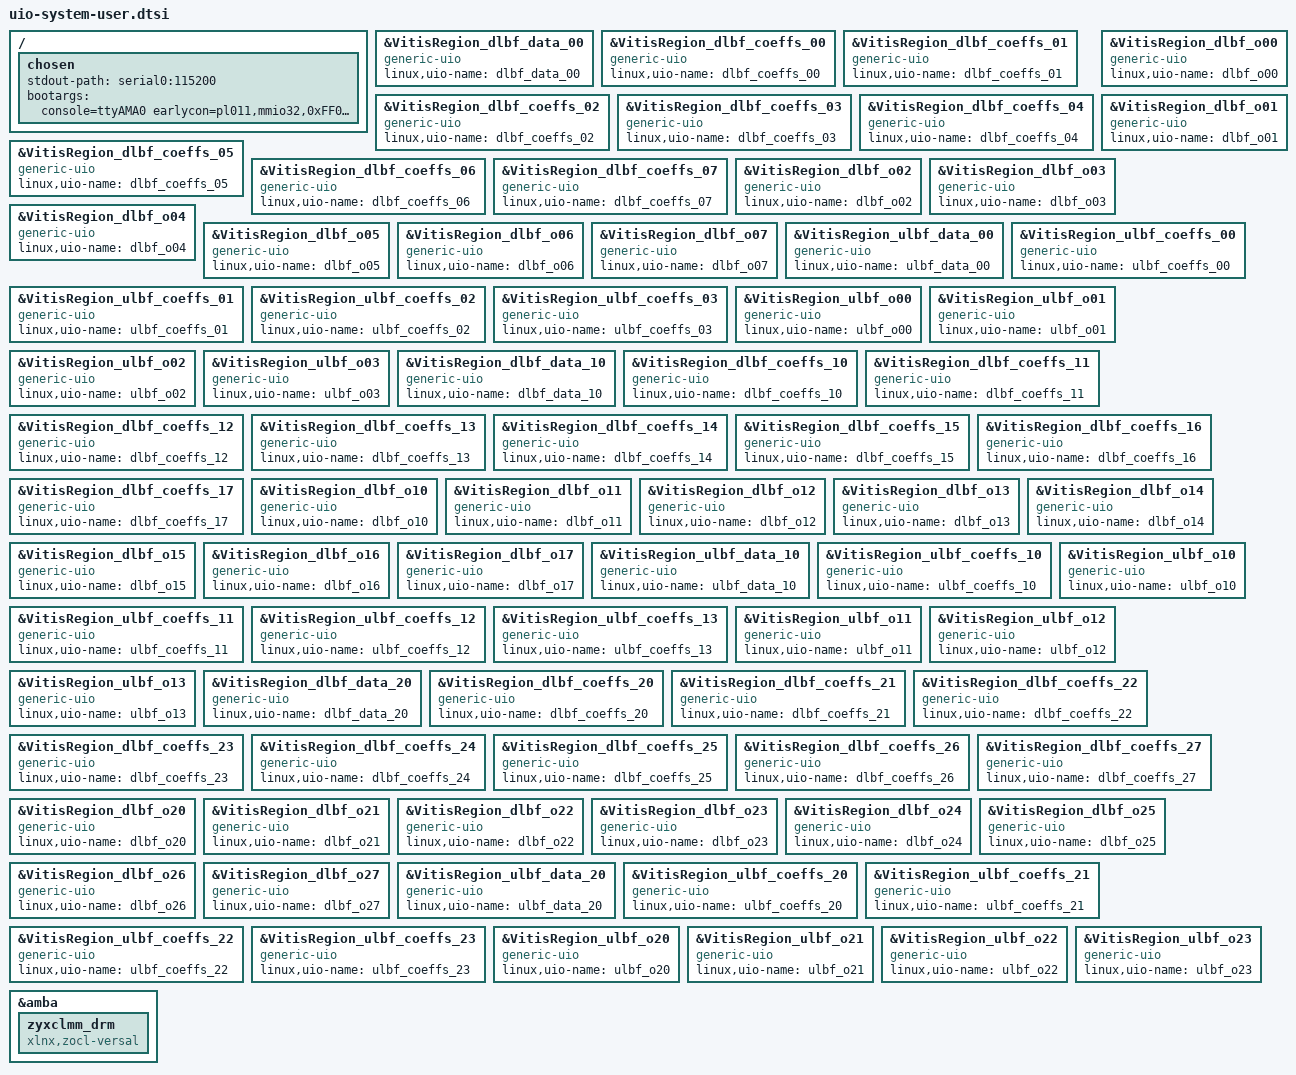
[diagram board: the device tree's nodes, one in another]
/include/ "system-conf.dtsi"
/ {
    chosen {
        stdout-path = "serial0:115200";
        bootargs = "console=ttyAMA0 earlycon=pl011,mmio32,0xFF000000,115200n8 clk_ignore_unused root=/dev/mmcblk0p2 rw rootwait rootfs=ext4 uio_pdrv_genirq.of_id=generic-uio";
        };
};


&VitisRegion_dlbf_data_00 {
    compatible = "generic-uio";
    linux,uio-name = "dlbf_data_00";
};

&VitisRegion_dlbf_coeffs_00 {
    compatible = "generic-uio";
    linux,uio-name = "dlbf_coeffs_00";
};

&VitisRegion_dlbf_coeffs_01 {
    compatible = "generic-uio";
    linux,uio-name = "dlbf_coeffs_01";
};

&VitisRegion_dlbf_coeffs_02 {
    compatible = "generic-uio";
    linux,uio-name = "dlbf_coeffs_02";
};

&VitisRegion_dlbf_coeffs_03 {
    compatible = "generic-uio";
    linux,uio-name = "dlbf_coeffs_03";
};

&VitisRegion_dlbf_coeffs_04 {
    compatible = "generic-uio";
    linux,uio-name = "dlbf_coeffs_04";
};

&VitisRegion_dlbf_coeffs_05 {
    compatible = "generic-uio";
    linux,uio-name = "dlbf_coeffs_05";
};

&VitisRegion_dlbf_coeffs_06 {
    compatible = "generic-uio";
    linux,uio-name = "dlbf_coeffs_06";
};

&VitisRegion_dlbf_coeffs_07 {
    compatible = "generic-uio";
    linux,uio-name = "dlbf_coeffs_07";
};

&VitisRegion_dlbf_o00 {
    compatible = "generic-uio";
    linux,uio-name = "dlbf_o00";
};

&VitisRegion_dlbf_o01 {
    compatible = "generic-uio";
    linux,uio-name = "dlbf_o01";
};

&VitisRegion_dlbf_o02 {
    compatible = "generic-uio";
    linux,uio-name = "dlbf_o02";
};

&VitisRegion_dlbf_o03 {
    compatible = "generic-uio";
    linux,uio-name = "dlbf_o03";
};

&VitisRegion_dlbf_o04 {
    compatible = "generic-uio";
    linux,uio-name = "dlbf_o04";
};

&VitisRegion_dlbf_o05 {
    compatible = "generic-uio";
    linux,uio-name = "dlbf_o05";
};

&VitisRegion_dlbf_o06 {
    compatible = "generic-uio";
    linux,uio-name = "dlbf_o06";
};

&VitisRegion_dlbf_o07 {
    compatible = "generic-uio";
    linux,uio-name = "dlbf_o07";
};

&VitisRegion_ulbf_data_00 {
    compatible = "generic-uio";
    linux,uio-name = "ulbf_data_00";
};

&VitisRegion_ulbf_coeffs_00 {
    compatible = "generic-uio";
    linux,uio-name = "ulbf_coeffs_00";
};

&VitisRegion_ulbf_coeffs_01 {
    compatible = "generic-uio";
    linux,uio-name = "ulbf_coeffs_01";
};

&VitisRegion_ulbf_coeffs_02 {
    compatible = "generic-uio";
    linux,uio-name = "ulbf_coeffs_02";
};

&VitisRegion_ulbf_coeffs_03 {
    compatible = "generic-uio";
    linux,uio-name = "ulbf_coeffs_03";
};

&VitisRegion_ulbf_o00 {
    compatible = "generic-uio";
    linux,uio-name = "ulbf_o00";
};

&VitisRegion_ulbf_o01 {
    compatible = "generic-uio";
    linux,uio-name = "ulbf_o01";
};

&VitisRegion_ulbf_o02 {
    compatible = "generic-uio";
    linux,uio-name = "ulbf_o02";
};

&VitisRegion_ulbf_o03 {
    compatible = "generic-uio";
    linux,uio-name = "ulbf_o03";
};

&VitisRegion_dlbf_data_10 {
    compatible = "generic-uio";
    linux,uio-name = "dlbf_data_10";
};

&VitisRegion_dlbf_coeffs_10 {
    compatible = "generic-uio";
    linux,uio-name = "dlbf_coeffs_10";
};

&VitisRegion_dlbf_coeffs_11 {
    compatible = "generic-uio";
    linux,uio-name = "dlbf_coeffs_11";
};

&VitisRegion_dlbf_coeffs_12 {
    compatible = "generic-uio";
    linux,uio-name = "dlbf_coeffs_12";
};

&VitisRegion_dlbf_coeffs_13 {
    compatible = "generic-uio";
    linux,uio-name = "dlbf_coeffs_13";
};

&VitisRegion_dlbf_coeffs_14 {
    compatible = "generic-uio";
    linux,uio-name = "dlbf_coeffs_14";
};

&VitisRegion_dlbf_coeffs_15 {
    compatible = "generic-uio";
    linux,uio-name = "dlbf_coeffs_15";
};

&VitisRegion_dlbf_coeffs_16 {
    compatible = "generic-uio";
    linux,uio-name = "dlbf_coeffs_16";
};

&VitisRegion_dlbf_coeffs_17 {
    compatible = "generic-uio";
    linux,uio-name = "dlbf_coeffs_17";
};

&VitisRegion_dlbf_o10 {
    compatible = "generic-uio";
    linux,uio-name = "dlbf_o10";
};

&VitisRegion_dlbf_o11 {
    compatible = "generic-uio";
    linux,uio-name = "dlbf_o11";
};

&VitisRegion_dlbf_o12 {
    compatible = "generic-uio";
    linux,uio-name = "dlbf_o12";
};

&VitisRegion_dlbf_o13 {
    compatible = "generic-uio";
    linux,uio-name = "dlbf_o13";
};

&VitisRegion_dlbf_o14 {
    compatible = "generic-uio";
    linux,uio-name = "dlbf_o14";
};

&VitisRegion_dlbf_o15 {
    compatible = "generic-uio";
    linux,uio-name = "dlbf_o15";
};

&VitisRegion_dlbf_o16 {
    compatible = "generic-uio";
    linux,uio-name = "dlbf_o16";
};

&VitisRegion_dlbf_o17 {
    compatible = "generic-uio";
    linux,uio-name = "dlbf_o17";
};

&VitisRegion_ulbf_data_10 {
    compatible = "generic-uio";
    linux,uio-name = "ulbf_data_10";
};

&VitisRegion_ulbf_coeffs_10 {
    compatible = "generic-uio";
    linux,uio-name = "ulbf_coeffs_10";
};

&VitisRegion_ulbf_coeffs_11 {
    compatible = "generic-uio";
    linux,uio-name = "ulbf_coeffs_11";
};

&VitisRegion_ulbf_coeffs_12 {
    compatible = "generic-uio";
    linux,uio-name = "ulbf_coeffs_12";
};

&VitisRegion_ulbf_coeffs_13 {
    compatible = "generic-uio";
    linux,uio-name = "ulbf_coeffs_13";
};

&VitisRegion_ulbf_o10 {
    compatible = "generic-uio";
    linux,uio-name = "ulbf_o10";
};

&VitisRegion_ulbf_o11 {
    compatible = "generic-uio";
    linux,uio-name = "ulbf_o11";
};

&VitisRegion_ulbf_o12 {
    compatible = "generic-uio";
    linux,uio-name = "ulbf_o12";
};

&VitisRegion_ulbf_o13 {
    compatible = "generic-uio";
    linux,uio-name = "ulbf_o13";
};

&VitisRegion_dlbf_data_20 {
    compatible = "generic-uio";
    linux,uio-name = "dlbf_data_20";
};

&VitisRegion_dlbf_coeffs_20 {
    compatible = "generic-uio";
    linux,uio-name = "dlbf_coeffs_20";
};

&VitisRegion_dlbf_coeffs_21 {
    compatible = "generic-uio";
    linux,uio-name = "dlbf_coeffs_21";
};

&VitisRegion_dlbf_coeffs_22 {
    compatible = "generic-uio";
    linux,uio-name = "dlbf_coeffs_22";
};

&VitisRegion_dlbf_coeffs_23 {
    compatible = "generic-uio";
    linux,uio-name = "dlbf_coeffs_23";
};

&VitisRegion_dlbf_coeffs_24 {
    compatible = "generic-uio";
    linux,uio-name = "dlbf_coeffs_24";
};

&VitisRegion_dlbf_coeffs_25 {
    compatible = "generic-uio";
    linux,uio-name = "dlbf_coeffs_25";
};

&VitisRegion_dlbf_coeffs_26 {
    compatible = "generic-uio";
    linux,uio-name = "dlbf_coeffs_26";
};

&VitisRegion_dlbf_coeffs_27 {
    compatible = "generic-uio";
    linux,uio-name = "dlbf_coeffs_27";
};

&VitisRegion_dlbf_o20 {
    compatible = "generic-uio";
    linux,uio-name = "dlbf_o20";
};

&VitisRegion_dlbf_o21 {
    compatible = "generic-uio";
    linux,uio-name = "dlbf_o21";
};

&VitisRegion_dlbf_o22 {
    compatible = "generic-uio";
    linux,uio-name = "dlbf_o22";
};

&VitisRegion_dlbf_o23 {
    compatible = "generic-uio";
    linux,uio-name = "dlbf_o23";
};

&VitisRegion_dlbf_o24 {
    compatible = "generic-uio";
    linux,uio-name = "dlbf_o24";
};

&VitisRegion_dlbf_o25 {
    compatible = "generic-uio";
    linux,uio-name = "dlbf_o25";
};

&VitisRegion_dlbf_o26 {
    compatible = "generic-uio";
    linux,uio-name = "dlbf_o26";
};

&VitisRegion_dlbf_o27 {
    compatible = "generic-uio";
    linux,uio-name = "dlbf_o27";
};

&VitisRegion_ulbf_data_20 {
    compatible = "generic-uio";
    linux,uio-name = "ulbf_data_20";
};

&VitisRegion_ulbf_coeffs_20 {
    compatible = "generic-uio";
    linux,uio-name = "ulbf_coeffs_20";
};

&VitisRegion_ulbf_coeffs_21 {
    compatible = "generic-uio";
    linux,uio-name = "ulbf_coeffs_21";
};

&VitisRegion_ulbf_coeffs_22 {
    compatible = "generic-uio";
    linux,uio-name = "ulbf_coeffs_22";
};

&VitisRegion_ulbf_coeffs_23 {
    compatible = "generic-uio";
    linux,uio-name = "ulbf_coeffs_23";
};

&VitisRegion_ulbf_o20 {
    compatible = "generic-uio";
    linux,uio-name = "ulbf_o20";
};

&VitisRegion_ulbf_o21 {
    compatible = "generic-uio";
    linux,uio-name = "ulbf_o21";
};

&VitisRegion_ulbf_o22 {
    compatible = "generic-uio";
    linux,uio-name = "ulbf_o22";
};

&VitisRegion_ulbf_o23 {
    compatible = "generic-uio";
    linux,uio-name = "ulbf_o23";
};

&amba {
    zyxclmm_drm {
        compatible = "xlnx,zocl-versal";
        status = "okay";
    };
};
